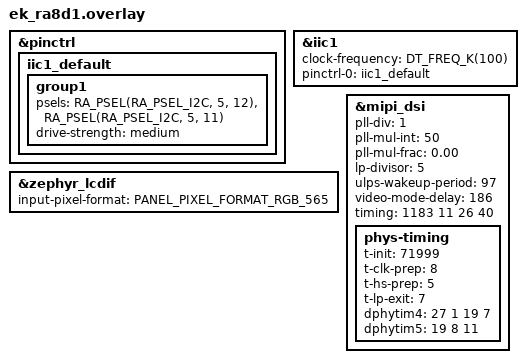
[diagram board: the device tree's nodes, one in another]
/*
 * Copyright (c) 2024 Renesas Electronics Corporation
 *
 * SPDX-License-Identifier: Apache-2.0
 */

&pinctrl {
	iic1_default: iic1_default {
		group1 {
			/* SCL1 SDA1 */
			psels = <RA_PSEL(RA_PSEL_I2C, 5, 12)>,
				<RA_PSEL(RA_PSEL_I2C, 5, 11)>;
			drive-strength = "medium";
		};
	};
};

&iic1 {
	status = "okay";
	#address-cells = <1>;
	#size-cells = <0>;
	clock-frequency = <DT_FREQ_K(100)>;
	pinctrl-0 = <&iic1_default>;
	pinctrl-names = "default";
};

&zephyr_lcdif {
	input-pixel-format = <PANEL_PIXEL_FORMAT_RGB_565>;
};

&mipi_dsi {
	status = "okay";
	pll-div = <1>;
	pll-mul-int = <50>;
	pll-mul-frac = "0.00";
	lp-divisor = <5>;
	ulps-wakeup-period = <97>;
	video-mode-delay = <186>;
	timing = <1183 11 26 40>;

	phys-timing {
		t-init = <71999>;
		t-clk-prep = <8>;
		t-hs-prep = <5>;
		t-lp-exit = <7>;
		dphytim4 = <27 1 19 7>;
		dphytim5 = <19 8 11>;
	};
};
